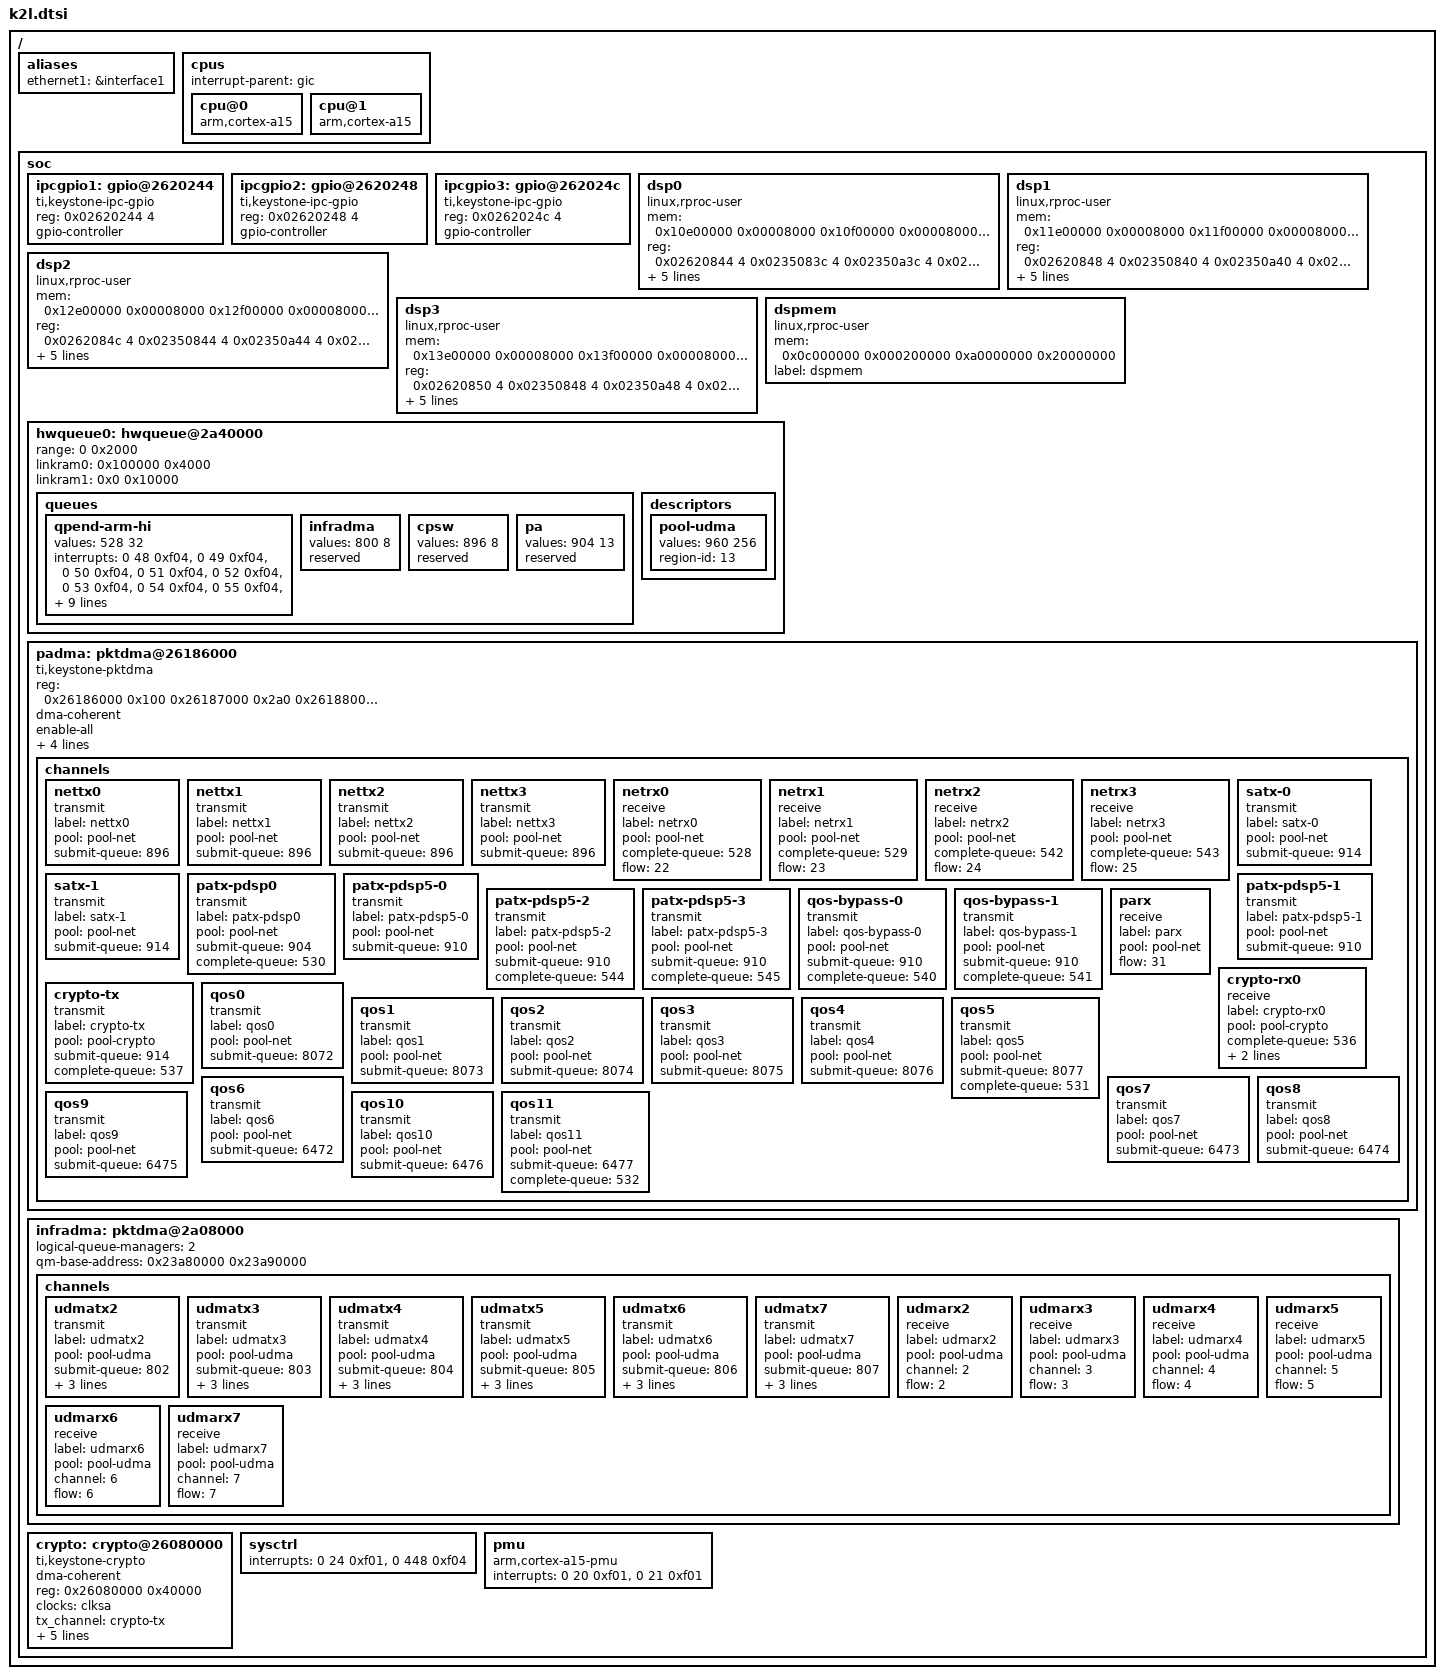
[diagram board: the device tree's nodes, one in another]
/*
 * Copyright 2014 Texas Instruments, Inc.
 *
 * Keystone Lamarr SoC specific device tree bindings
 *
 * This program is free software; you can redistribute it and/or modify
 * it under the terms of the GNU General Public License version 2 as
 * published by the Free Software Foundation.
 */

/ {
	aliases {
		ethernet1 = &interface1;
	};

	cpus {
		interrupt-parent = <&gic>;

		cpu@0 {
			compatible = "arm,cortex-a15";
		};

		cpu@1 {
			compatible = "arm,cortex-a15";
		};
	};

	soc {
		/include/ "k2l-clocks.dtsi"

		ipcgpio1: gpio@2620244 {
			compatible = "ti,keystone-ipc-gpio";
			reg = <0x02620244 4>;
			gpio-controller;
			#gpio-cells = <2>;
		};

		ipcgpio2: gpio@2620248 {
			compatible = "ti,keystone-ipc-gpio";
			reg = <0x02620248 4>;
			gpio-controller;
			#gpio-cells = <2>;
		};

		ipcgpio3: gpio@262024c {
			compatible = "ti,keystone-ipc-gpio";
			reg = <0x0262024c 4>;
			gpio-controller;
			#gpio-cells = <2>;
		};

		dsp0: dsp0 {
			compatible = "linux,rproc-user";
			mem = <0x10e00000 0x00008000
			       0x10f00000 0x00008000
			       0x10800000 0x00100000>;
			reg = <0x02620844 4
			       0x0235083c 4
			       0x02350a3c 4
			       0x02620240 4>;
			reg-names = "boot-address", "psc-mdstat", "psc-mdctl",
				"ipcgr";
			interrupt-parent = <&ipcirq0>;
			interrupts = <8 0 0 0>;
			kick-gpio = <&ipcgpio0 27 0>;
			clocks = <&clkgem0>;
			label = "dsp0";
		};

		dsp1: dsp1 {
			compatible = "linux,rproc-user";
			mem = <0x11e00000 0x00008000
			       0x11f00000 0x00008000
			       0x11800000 0x00100000>;
			reg = <0x02620848 4
			       0x02350840 4
			       0x02350a40 4
			       0x02620244 4>;
			reg-names = "boot-address", "psc-mdstat", "psc-mdctl",
				"ipcgr";
			interrupt-parent = <&ipcirq0>;
			interrupts = <9 0 1 0>;
			kick-gpio = <&ipcgpio1 27 0>;
			clocks = <&clkgem1>;
			label = "dsp1";
		};

		dsp2: dsp2 {
			compatible = "linux,rproc-user";
			mem = <0x12e00000 0x00008000
			       0x12f00000 0x00008000
			       0x12800000 0x00100000>;
			reg = <0x0262084c 4
			       0x02350844 4
			       0x02350a44 4
			       0x02620248 4>;
			reg-names = "boot-address", "psc-mdstat", "psc-mdctl",
				"ipcgr";
			interrupt-parent = <&ipcirq0>;
			interrupts = <10 0 2 0>;
			kick-gpio = <&ipcgpio2 27 0>;
			clocks = <&clkgem2>;
			label = "dsp2";
		};

		dsp3: dsp3 {
			compatible = "linux,rproc-user";
			mem = <0x13e00000 0x00008000
			       0x13f00000 0x00008000
			       0x13800000 0x00100000>;
			reg = <0x02620850 4
			       0x02350848 4
			       0x02350a48 4
			       0x0262024c 4>;
			reg-names = "boot-address", "psc-mdstat", "psc-mdctl",
				"ipcgr";
			interrupt-parent = <&ipcirq0>;
			interrupts = <11 0 3 0>;
			kick-gpio = <&ipcgpio3 27 0>;
			clocks = <&clkgem3>;
			label = "dsp3";
		};

		dspmem: dspmem {
			compatible = "linux,rproc-user";
			mem  = <0x0c000000 0x000200000
					0xa0000000 0x20000000>;
			label = "dspmem";
		};

		hwqueue0: hwqueue@2a40000 {
			range		= <0 0x2000>;
			linkram0	= <0x100000 0x4000>;
			linkram1	= <0x0 0x10000>;

			queues {
				qpend-arm-hi {
					values = <528 32>;
					interrupts = <0 48 0xf04>,
						<0 49 0xf04>,
						<0 50 0xf04>,
						<0 51 0xf04>,
						<0 52 0xf04>,
						<0 53 0xf04>,
						<0 54 0xf04>,
						<0 55 0xf04>,
						<0 56 0xf04>,
						<0 57 0xf04>,
						<0 58 0xf04>,
						<0 59 0xf04>,
						<0 60 0xf04>,
						<0 61 0xf04>,
						<0 62 0xf04>,
						<0 63 0xf04>,
						<0 64 0xf04>,
						<0 65 0xf04>,
						<0 66 0xf04>,
						<0 67 0xf04>,
						<0 68 0xf04>,
						<0 69 0xf04>,
						<0 70 0xf04>,
						<0 71 0xf04>,
						<0 72 0xf04>,
						<0 73 0xf04>,
						<0 74 0xf04>,
						<0 75 0xf04>,
						<0 76 0xf04>,
						<0 77 0xf04>,
						<0 78 0xf04>,
						<0 79 0xf04>;
					reserved;
				};
				infradma {
					values = <800 8>;
					reserved;
				};
				cpsw {
					values = <896 8>;
					reserved;
				};
				pa {
					values = <904 13>;
					reserved;
				};
			};
			descriptors {
				pool-udma {
					values = <960 256>;	/* num_desc desc_size */
					region-id = <13>;
				};
			};
		}; /* hwqueue0 */

		padma: pktdma@26186000 {
			compatible = "ti,keystone-pktdma";
			reg = <0x26186000 0x100		/* 0 - global  */
			       0x26187000 0x2a0		/* 1 - txchan  */
			       0x26188000 0xb60		/* 2 - rxchan  */
			       0x26186100 0x80		/* 3 - txsched */
			       0x26189000 0x1000>;	/* 4 - rxflow  */
			/* loop-back;  */
			/* bigendian; */
			dma-coherent;
			enable-all;
			/* debug; */
			/* rx-priority = <0>; */
			/* tx-priority = <0>; */
			rx-retry-timeout = <3500>; /* Number of pktdma cycles
						      to wait before retry on
						      buffer starvation */
			logical-queue-managers	= <2>;
			queues-per-queue-manager = <4096>;
			qm-base-address = <0x23a80000 0x23a90000>;

			channels {
				nettx0 {
					transmit;
					label		= "nettx0";
					pool		= "pool-net";
					submit-queue	= <896>;
					/* complete-queue = <xx>; */
					/* debug; */
					/* channel = <0>; */
					/* priority = <1>; */
				};
				nettx1 {
					transmit;
					label		= "nettx1";
					pool		= "pool-net";
					submit-queue	= <896>;
					/* complete-queue = <xx>; */
					/* debug; */
					/* channel = <0>; */
					/* priority = <1>; */
				};
				nettx2 {
					transmit;
					label		= "nettx2";
					pool		= "pool-net";
					submit-queue	= <896>;
					/* complete-queue = <xx>; */
					/* debug; */
					/* channel = <0>; */
					/* priority = <1>; */
				};
				nettx3 {
					transmit;
					label		= "nettx3";
					pool		= "pool-net";
					submit-queue	= <896>;
					/* complete-queue = <xx>; */
					/* debug; */
					/* channel = <0>; */
					/* priority = <1>; */
				};
				netrx0 {
					receive;
					label		= "netrx0";
					pool		= "pool-net";
					/* submit-queue   = <xx>; */
					complete-queue = <528>;
					/* debug; */
					/* channel = <0>; */
					flow		= <22>;
				};
				netrx1 {
					receive;
					label		= "netrx1";
					pool		= "pool-net";
					/* submit-queue   = <xx>; */
					complete-queue = <529>;
					/* debug; */
					/* channel = <0>; */
					flow		= <23>;
				};
				netrx2 {
					receive;
					label		= "netrx2";
					pool		= "pool-net";
					/* submit-queue   = <xx>; */
					complete-queue = <542>;
					/* debug; */
					/* channel = <0>; */
					flow		= <24>;
				};
				netrx3 {
					receive;
					label		= "netrx3";
					pool		= "pool-net";
					/* submit-queue   = <xx>; */
					complete-queue = <543>;
					/* debug; */
					/* channel = <0>; */
					flow		= <25>;
				};
				satx-0 {
					transmit;
					label		= "satx-0";
					pool		= "pool-net";
					submit-queue	= <914>;
				};
				satx-1 {
					transmit;
					label		= "satx-1";
					pool		= "pool-net";
					submit-queue	= <914>;
				};
				patx-pdsp0 {
					transmit;
					label		= "patx-pdsp0";
					pool		= "pool-net";
					submit-queue	= <904>;
					complete-queue  = <530>;
					/* debug; */
					/* channel = <xx>; */
					/* priority = <1>; */
				};
				patx-pdsp5-0 {
					transmit;
					label		= "patx-pdsp5-0";
					pool		= "pool-net";
					submit-queue	= <910>;
					/* complete-queue = <xx>; */
					/* debug; */
					/* channel = <xx>; */
					/* priority = <1>; */
				};
				patx-pdsp5-1 {
					transmit;
					label		= "patx-pdsp5-1";
					pool		= "pool-net";
					submit-queue	= <910>;
					/* complete-queue = <xx>; */
					/* debug; */
					/* channel = <xx>; */
					/* priority = <1>; */
				};
				patx-pdsp5-2 {
					transmit;
					label		= "patx-pdsp5-2";
					pool		= "pool-net";
					submit-queue	= <910>;
					complete-queue = <544>;
					/* debug; */
					/* channel = <xx>; */
					/* priority = <1>; */
				};
				patx-pdsp5-3 {
					transmit;
					label		= "patx-pdsp5-3";
					pool		= "pool-net";
					submit-queue	= <910>;
					complete-queue = <545>;
					/* debug; */
					/* channel = <xx>; */
					/* priority = <1>; */
				};
				qos-bypass-0 {
					transmit;
					label		= "qos-bypass-0";
					pool		= "pool-net";
					submit-queue	= <910>;
					complete-queue = <540>;
					/* debug; */
					/* channel = <xx>; */
					/* priority = <1>; */
				};
				qos-bypass-1 {
					transmit;
					label		= "qos-bypass-1";
					pool		= "pool-net";
					submit-queue	= <910>;
					complete-queue = <541>;
					/* debug; */
					/* channel = <xx>; */
					/* priority = <1>; */
				};
				parx {
					receive;
					label		= "parx";
					pool		= "pool-net";
					/* submit-queue   = <xx>; */
					/* complete-queue = <xx>; */
					/* debug; */
					/* channel = <0>; */
					flow		= <31>;
				};
				crypto-rx0 {
					receive;
					label		= "crypto-rx0";
					pool		= "pool-crypto";
					complete-queue 	= <536>;
					flow		= <26>;
					rx-error-retry; /* enable retry on
							   buffer starvation */
					/* debug; */
				};
				crypto-tx {
					transmit;
					label		= "crypto-tx";
					pool		= "pool-crypto";
					submit-queue	= <914>;
					complete-queue 	= <537>;
					/* debug; */
				};
				qos0 {
					transmit;
					label		= "qos0";
					pool		= "pool-net";
					submit-queue	= <8072>;
					/* complete-queue = <xx>; */
					/* debug; */
					/* channel = <xx>; */
					/* priority = <1>; */
				};
				qos1 {
					transmit;
					label		= "qos1";
					pool		= "pool-net";
					submit-queue	= <8073>;
					/* complete-queue = <xx>; */
					/* debug; */
					/* channel = <xx>; */
					/* priority = <1>; */
				};
				qos2 {
					transmit;
					label		= "qos2";
					pool		= "pool-net";
					submit-queue	= <8074>;
					/* complete-queue = <xx>; */
					/* debug; */
					/* channel = <xx>; */
					/* priority = <1>; */
				};
				qos3 {
					transmit;
					label		= "qos3";
					pool		= "pool-net";
					submit-queue	= <8075>;
					/* complete-queue = <xx>; */
					/* debug; */
					/* channel = <xx>; */
					/* priority = <1>; */
				};
				qos4 {
					transmit;
					label		= "qos4";
					pool		= "pool-net";
					submit-queue	= <8076>;
					/* complete-queue = <xx>; */
					/* debug; */
					/* channel = <xx>; */
					/* priority = <1>; */
				};
				qos5 {
					transmit;
					label		= "qos5";
					pool		= "pool-net";
					submit-queue	= <8077>;
					complete-queue  = <531>;
					/* debug; */
					/* channel = <xx>; */
					/* priority = <1>; */
				};
				qos6 {
					transmit;
					label		= "qos6";
					pool		= "pool-net";
					submit-queue	= <6472>;
					/* complete-queue = <xx>; */
					/* debug; */
					/* channel = <xx>; */
					/* priority = <1>; */
				};
				qos7 {
					transmit;
					label		= "qos7";
					pool		= "pool-net";
					submit-queue	= <6473>;
					/* complete-queue = <xx>; */
					/* debug; */
					/* channel = <xx>; */
					/* priority = <1>; */
				};
				qos8 {
					transmit;
					label		= "qos8";
					pool		= "pool-net";
					submit-queue	= <6474>;
					/* complete-queue = <xx>; */
					/* debug; */
					/* channel = <xx>; */
					/* priority = <1>; */
				};
				qos9 {
					transmit;
					label		= "qos9";
					pool		= "pool-net";
					submit-queue	= <6475>;
					/* complete-queue = <xx>; */
					/* debug; */
					/* channel = <xx>; */
					/* priority = <1>; */
				};
				qos10 {
					transmit;
					label		= "qos10";
					pool		= "pool-net";
					submit-queue	= <6476>;
					/* complete-queue = <xx>; */
					/* debug; */
					/* channel = <xx>; */
					/* priority = <1>; */
				};
				qos11 {
					transmit;
					label		= "qos11";
					pool		= "pool-net";
					submit-queue	= <6477>;
					complete-queue  = <532>;
					/* debug; */
					/* channel = <xx>; */
					/* priority = <1>; */
				};
			};
		};

		infradma: pktdma@2a08000 {
			logical-queue-managers	= <2>;
			qm-base-address = <0x23a80000 0x23a90000>;

			channels {
				udmatx2 {
					transmit;
					label		= "udmatx2";
					pool		= "pool-udma";
					submit-queue	= <802>;
					/* complete-queue  = <2> */
					/* debug; */
					channel		= <2>;
					priority	= <1>;
					flowtag		= <2>;
				};
				udmatx3 {
					transmit;
					label		= "udmatx3";
					pool		= "pool-udma";
					submit-queue	= <803>;
					/* complete-queue  = <3> */
					/* debug; */
					channel		= <3>;
					priority	= <1>;
					flowtag		= <3>;
				};
				udmatx4 {
					transmit;
					label		= "udmatx4";
					pool		= "pool-udma";
					submit-queue	= <804>;
					/* complete-queue  = <4> */
					/* debug; */
					channel		= <4>;
					priority	= <1>;
					flowtag		= <4>;
				};
				udmatx5 {
					transmit;
					label		= "udmatx5";
					pool		= "pool-udma";
					submit-queue	= <805>;
					/* complete-queue  = <5> */
					/* debug; */
					channel		= <5>;
					priority	= <1>;
					flowtag		= <5>;
				};
				udmatx6 {
					transmit;
					label		= "udmatx6";
					pool		= "pool-udma";
					submit-queue	= <806>;
					/* complete-queue  = <6> */
					/* debug; */
					channel		= <6>;
					priority	= <1>;
					flowtag		= <6>;
				};
				udmatx7 {
					transmit;
					label		= "udmatx7";
					pool		= "pool-udma";
					submit-queue	= <807>;
					/* complete-queue  = <7> */
					/* debug; */
					channel		= <7>;
					priority	= <1>;
					flowtag		= <7>;
				};
				udmarx2 {
					receive;
					label		= "udmarx2";
					pool		= "pool-udma";
					/* submit-queue = <xx>; */
					/* complete-queue  = <18> */
					/* debug; */
					channel		= <2>;
					flow		= <2>;
				};
				udmarx3 {
					receive;
					label		= "udmarx3";
					pool		= "pool-udma";
					/* submit-queue = <xx>; */
					/* complete-queue  = <19> */
					/* debug; */
					channel		= <3>;
					flow		= <3>;
				};
				udmarx4 {
					receive;
					label		= "udmarx4";
					pool		= "pool-udma";
					/* submit-queue = <xx>; */
					/* complete-queue  = <20> */
					/* debug; */
					channel		= <4>;
					flow		= <4>;
				};
				udmarx5 {
					receive;
					label		= "udmarx5";
					pool		= "pool-udma";
					/* submit-queue = <xx>; */
					/* complete-queue  = <21> */
					/* debug; */
					channel		= <5>;
					flow		= <5>;
				};
				udmarx6 {
					receive;
					label		= "udmarx6";
					pool		= "pool-udma";
					/* submit-queue = <xx>; */
					/* complete-queue  = <22> */
					/* debug; */
					channel		= <6>;
					flow		= <6>;
				};
				udmarx7 {
					receive;
					label		= "udmarx7";
					pool		= "pool-udma";
					/* submit-queue = <xx>; */
					/* complete-queue  = <23> */
					/* debug; */
					channel		= <7>;
					flow		= <7>;
				};
			};
		};

		/include/ "k2l-net.dtsi"

		crypto: crypto@26080000 {
			compatible = "ti,keystone-crypto";
			dma-coherent;
			reg = <0x26080000 0x40000>;
			clocks = <&clksa>;
			tx_channel = "crypto-tx";
			tx_queue_depth = <256>;

			rx_channel = "crypto-rx0";
			rx_queue_depth = <256 64 0 0>;
			rx_buffer_size = <1500 4096 0 0>;

			sc-id = <0x7000 0x71ff>;
		};

		sysctrl {
			interrupts = <0 24 0xf01>, /* L1L2 ECC error interrupt */
				     <0 448 0xf04>; /* DDR3 ECC error interrupt */
		};

		pmu {
			compatible = "arm,cortex-a15-pmu";
			interrupts = <0 20 0xf01>,
				     <0 21 0xf01>;
		};
	};
};
